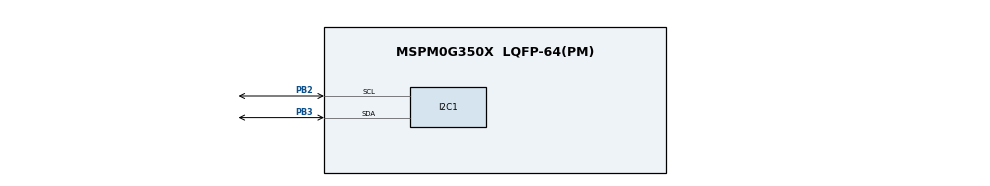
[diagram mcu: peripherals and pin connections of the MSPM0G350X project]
/**
 * @cliArgs --device "MSPM0G350X" --part "Default" --package "LQFP-64(PM)" --product "mspm0_sdk@2.04.00.06"
 * @versions {"tool":"1.23.0+4000"}
 */

/**
 * Import the modules used in this configuration.
 */
const I2C           = scripting.addModule("/ti/driverlib/I2C", {}, false);
const I2C1          = I2C.addInstance();
const SYSCTL        = scripting.addModule("/ti/driverlib/SYSCTL");
const ProjectConfig = scripting.addModule("/ti/project_config/ProjectConfig");

/**
 * Write custom configuration values to the imported modules.
 */
I2C1.$name                             = "I2C_OLED";
I2C1.basicEnableController             = true;
I2C1.basicControllerStandardBusSpeed   = "Fast";
I2C1.peripheral.$assign                = "I2C1";
I2C1.peripheral.sdaPin.$assign         = "PB3";
I2C1.peripheral.sclPin.$assign         = "PB2";
I2C1.sdaPinConfig.$name                = "ti_driverlib_gpio_GPIOPinGeneric0";
I2C1.sdaPinConfig.hideOutputInversion  = scripting.forceWrite(false);
I2C1.sdaPinConfig.onlyInternalResistor = scripting.forceWrite(false);
I2C1.sdaPinConfig.passedPeripheralType = scripting.forceWrite("Digital");
I2C1.sclPinConfig.$name                = "ti_driverlib_gpio_GPIOPinGeneric1";
I2C1.sclPinConfig.hideOutputInversion  = scripting.forceWrite(false);
I2C1.sclPinConfig.onlyInternalResistor = scripting.forceWrite(false);
I2C1.sclPinConfig.passedPeripheralType = scripting.forceWrite("Digital");

const Board = scripting.addModule("/ti/driverlib/Board", {}, false);

SYSCTL.forceDefaultClkConfig = true;

/**
 * Pinmux solution for unlocked pins/peripherals. This ensures that minor changes to the automatic solver in a future
 * version of the tool will not impact the pinmux you originally saw.  These lines can be completely deleted in order to
 * re-solve from scratch.
 */
Board.peripheral.$suggestSolution          = "DEBUGSS";
Board.peripheral.swclkPin.$suggestSolution = "PA20";
Board.peripheral.swdioPin.$suggestSolution = "PA19";
SYSCTL.peripheral.$suggestSolution         = "SYSCTL";
